/* BMW AG */
/* All rights reserved */
/* Description: LIN Description file */
/* Konfiguration: UKL_KW17_15 [13] */
/* Konfigurationsstand: F056-16-11-400 (Freeze KW17/15) */
/* Bus: M_LIN_6_V2 */

LIN_description_file;
LIN_protocol_version = "2.2";
LIN_language_version = "2.2";
LIN_speed = 19.2 kbps;
Channel_name = "M_LIN_6";

Nodes {
  Master: DME1_BK, 10 ms, 0.1 ms ;
  Slaves: EWP20, EWP22, EWP23 ;
}

Signals {
  AVL_VL_RPM_EWP20_LIN: 8, 255, EWP20, DME1_BK ;
  AVL_VL_RPM_EWP22_LIN: 8, 255, EWP22, DME1_BK ;
  AVL_VL_RPM_EWP23_LIN: 8, 255, EWP23, DME1_BK ;
  COMM_ERR_EWP20_LIN: 1, 0, EWP20, DME1_BK ;
  COMM_ERR_EWP22_LIN: 1, 0, EWP22, DME1_BK ;
  COMM_ERR_EWP23_LIN: 1, 0, EWP23, DME1_BK ;
   ERR_ST_BLK_EWP20_LIN: 2, 3, EWP20, DME1_BK ;
  ERR_ST_BLK_EWP22_LIN: 2, 3, EWP22, DME1_BK ;
  ERR_ST_BLK_EWP23_LIN: 2, 3, EWP23, DME1_BK ;
  ERR_ST_DRYR_EWP20_LIN: 2, 3, EWP20, DME1_BK ;
  ERR_ST_DRYR_EWP22_LIN: 2, 3, EWP22, DME1_BK ;
  ERR_ST_DRYR_EWP23_LIN: 2, 3, EWP23, DME1_BK ;
  ERR_ST_ERR_EL_EWP20_LIN: 2, 3, EWP20, DME1_BK ;
  ERR_ST_ERR_EL_EWP22_LIN: 2, 3, EWP22, DME1_BK ;
  ERR_ST_ERR_EL_EWP23_LIN: 2, 3, EWP23, DME1_BK ;
  ERR_ST_OCU_EWP20_LIN: 2, 3, EWP20, DME1_BK ;
  ERR_ST_OCU_EWP22_LIN: 2, 3, EWP22, DME1_BK ;
  ERR_ST_OCU_EWP23_LIN: 2, 3, EWP23, DME1_BK ;
  ERR_ST_OTMP_EWP20_LIN: 2, 3, EWP20, DME1_BK ;
  ERR_ST_OTMP_EWP22_LIN: 2, 3, EWP22, DME1_BK ;
  ERR_ST_OTMP_EWP23_LIN: 2, 3, EWP23, DME1_BK ;
  ERR_ST_U_EWP20_LIN: 2, 3, EWP20, DME1_BK ;
  ERR_ST_U_EWP22_LIN: 2, 3, EWP22, DME1_BK ;
  ERR_ST_U_EWP23_LIN: 2, 3, EWP23, DME1_BK ;
  I_EWP20_LIN: 8, 255, EWP20, DME1_BK ;
  I_EWP22_LIN: 8, 255, EWP22, DME1_BK ;
  I_EWP23_LIN: 8, 255, EWP23, DME1_BK ;
  ST_RPM_MONI_EWP20_LIN: 2, 3, EWP20, DME1_BK ;
  ST_RPM_MONI_EWP22_LIN: 2, 3, EWP22, DME1_BK ;
  ST_RPM_MONI_EWP23_LIN: 2, 3, EWP23, DME1_BK ;
  ST_TARVL_RPM_EWP20_LIN: 8, 255, EWP20, DME1_BK ;
  ST_TARVL_RPM_EWP22_LIN: 8, 255, EWP22, DME1_BK ;
  ST_TARVL_RPM_EWP23_LIN: 8, 255, EWP23, DME1_BK ;
  TARVL_RPM_EWP20_LIN: 8, 255, DME1_BK, EWP20 ;
  TARVL_RPM_EWP22_LIN: 8, 255, DME1_BK, EWP22 ;
  TARVL_RPM_EWP23_LIN: 8, 255, DME1_BK, EWP23 ;
  TEMP_EWP20_LIN: 8, 255, EWP20, DME1_BK ;
  TEMP_EWP22_LIN: 8, 255, EWP22, DME1_BK ;
  TEMP_EWP23_LIN: 8, 255, EWP23, DME1_BK ;
  U_EWP20_LIN: 8, 255, EWP20, DME1_BK ;
  U_EWP22_LIN: 8, 255, EWP22, DME1_BK ;
  U_EWP23_LIN: 8, 255, EWP23, DME1_BK ;
}

Frames {
  CTR_EWP20_LIN: 38, DME1_BK, 2 {
    TARVL_RPM_EWP20_LIN, 0 ;
  }
  CTR_EWP22_LIN: 40, DME1_BK, 2 {
    TARVL_RPM_EWP22_LIN, 0 ;
  }
  CTR_EWP23_LIN: 57, DME1_BK, 2 {
    TARVL_RPM_EWP23_LIN, 0 ;
  }
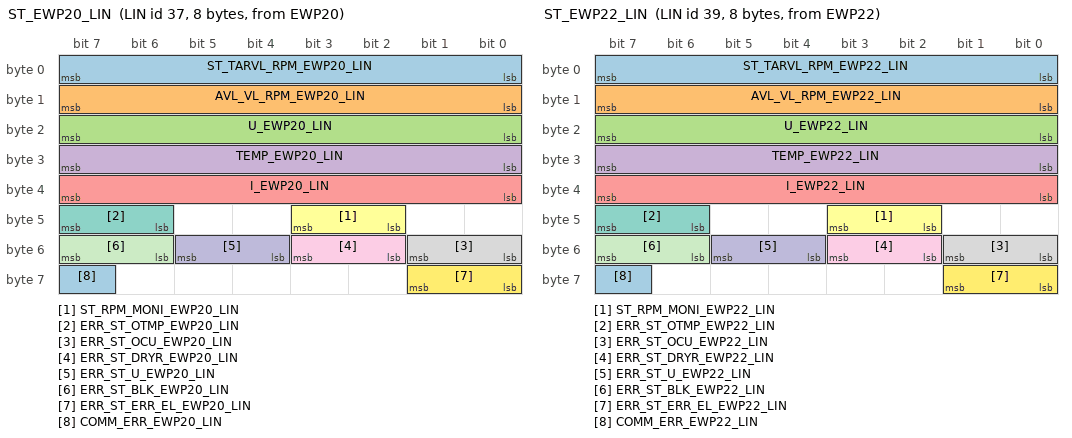
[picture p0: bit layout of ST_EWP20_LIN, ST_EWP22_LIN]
  ST_EWP20_LIN: 37, EWP20, 8 {
    ST_TARVL_RPM_EWP20_LIN, 0 ;
    AVL_VL_RPM_EWP20_LIN, 8 ;
    U_EWP20_LIN, 16 ;
    TEMP_EWP20_LIN, 24 ;
    I_EWP20_LIN, 32 ;
    ST_RPM_MONI_EWP20_LIN, 42 ;
    ERR_ST_OTMP_EWP20_LIN, 46 ;
    ERR_ST_OCU_EWP20_LIN, 48 ;
    ERR_ST_DRYR_EWP20_LIN, 50 ;
    ERR_ST_U_EWP20_LIN, 52 ;
    ERR_ST_BLK_EWP20_LIN, 54 ;
    ERR_ST_ERR_EL_EWP20_LIN, 56 ;
    COMM_ERR_EWP20_LIN, 63 ;
  }
  ST_EWP22_LIN: 39, EWP22, 8 {
    ST_TARVL_RPM_EWP22_LIN, 0 ;
    AVL_VL_RPM_EWP22_LIN, 8 ;
    U_EWP22_LIN, 16 ;
    TEMP_EWP22_LIN, 24 ;
    I_EWP22_LIN, 32 ;
    ST_RPM_MONI_EWP22_LIN, 42 ;
    ERR_ST_OTMP_EWP22_LIN, 46 ;
    ERR_ST_OCU_EWP22_LIN, 48 ;
    ERR_ST_DRYR_EWP22_LIN, 50 ;
    ERR_ST_U_EWP22_LIN, 52 ;
    ERR_ST_BLK_EWP22_LIN, 54 ;
    ERR_ST_ERR_EL_EWP22_LIN, 56 ;
    COMM_ERR_EWP22_LIN, 63 ;
  }
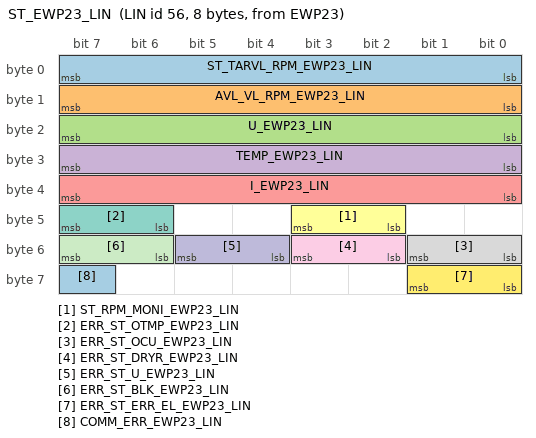
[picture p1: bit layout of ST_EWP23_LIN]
  ST_EWP23_LIN: 56, EWP23, 8 {
    ST_TARVL_RPM_EWP23_LIN, 0 ;
    AVL_VL_RPM_EWP23_LIN, 8 ;
    U_EWP23_LIN, 16 ;
    TEMP_EWP23_LIN, 24 ;
    I_EWP23_LIN, 32 ;
    ST_RPM_MONI_EWP23_LIN, 42 ;
    ERR_ST_OTMP_EWP23_LIN, 46 ;
    ERR_ST_OCU_EWP23_LIN, 48 ;
    ERR_ST_DRYR_EWP23_LIN, 50 ;
    ERR_ST_U_EWP23_LIN, 52 ;
    ERR_ST_BLK_EWP23_LIN, 54 ;
    ERR_ST_ERR_EL_EWP23_LIN, 56 ;
    COMM_ERR_EWP23_LIN, 63 ;
  }
}

Node_attributes {
  EWP20{
    LIN_protocol = "2.1" ;
    configured_NAD = 0x50 ;
    initial_NAD = 0x50 ;
    product_id = 0x40, 0x700F, 0 ;
    response_error = COMM_ERR_EWP20_LIN ;
    P2_min = 50 ms ;
    ST_min = 0 ms ;
    N_As_timeout = 1000 ms ;
    N_Cr_timeout = 1000 ms ;
    configurable_frames {
      ST_EWP20_LIN ;
      CTR_EWP20_LIN ;
    }
  }
  EWP22{
    LIN_protocol = "2.1" ;
    configured_NAD = 0x5A ;
    initial_NAD = 0x5A ;
    product_id = 0x40, 0x700F, 0 ;
    response_error = COMM_ERR_EWP22_LIN ;
    P2_min = 50 ms ;
    ST_min = 0 ms ;
    N_As_timeout = 1000 ms ;
    N_Cr_timeout = 1000 ms ;
    configurable_frames {
      ST_EWP22_LIN ;
      CTR_EWP22_LIN ;
    }
  }
  EWP23{
    LIN_protocol = "2.1" ;
    configured_NAD = 0x4B ;
    initial_NAD = 0x4B ;
    product_id = 0x40, 0x700F, 0 ;
    response_error = COMM_ERR_EWP23_LIN ;
    P2_min = 50 ms ;
    ST_min = 0 ms ;
    N_As_timeout = 1000 ms ;
    N_Cr_timeout = 1000 ms ;
    configurable_frames {
      ST_EWP23_LIN ;
      CTR_EWP23_LIN ;
    }
  }
}

Schedule_tables {
 DIAG {
    MasterReq delay 10 ms ;
    SlaveResp delay 10 ms ;
  }
 DIAG_RESP {
    SlaveResp delay 10 ms ;
  }
 DIAG_RQ {
    MasterReq delay 10 ms ;
  }
 RUN_EWP22 {
    CTR_EWP22_LIN delay 10 ms ;
    ST_EWP22_LIN delay 20 ms ;
  }
 RUN_EWP20 {
  CTR_EWP20_LIN delay 20 ms ;
    ST_EWP20_LIN delay 10 ms ;
  }
 RUN_EWP23 {
    CTR_EWP23_LIN delay 20 ms ;
  ST_EWP23_LIN delay 20 ms ;
  }
}

Signal_encoding_types {
  AVL_VL_RPM_EWP20_LIN {
    physical_value, 0, 254, 1, 0 ;
    logical_value, 255, "Signal ungultig" ;
  }
  COMM_ERR_EWP20_LIN {
    logical_value, 0, "kein Fehler" ;
    logical_value, 1, "Fehler aktiv" ;
  }
  ERR_ST_BLK_EWP20_LIN {
    logical_value, 0, "Keine Blockierung" ;
    logical_value, 1, "Blockierung" ;
    logical_value, 3, "BLK Signal ungultig" ;
  }
  ERR_ST_DRYR_EWP20_LIN {
    logical_value, 0, "kein Trockenlauf" ;
    logical_value, 1, "Trockenlauf" ;
    logical_value, 3, "DRYR Signal ungultig" ;
  }
  ERR_ST_ERR_EL_EWP20_LIN {
    logical_value, 0, "Kein interner Fehler erkannt" ;
    logical_value, 1, "Unplausible Temperatur-, Spannungs-, Strommessung erkannt" ;
    logical_value, 3, "ERR Signal ungultig" ;
  }
  ERR_ST_OCU_EWP20_LIN {
    logical_value, 0, "kein uberstrom" ;
    logical_value, 1, "Uberstromabschaltung" ;
    logical_value, 2, "Uberstromabregelung" ;
    logical_value, 3, "OCU Signal ungultig" ;
  }
  ERR_ST_OTMP_EWP20_LIN {
    logical_value, 0, "keine obertemperatur" ;
    logical_value, 1, "obertemperatur" ;
    logical_value, 2, "Abregeltemperatur" ;
    logical_value, 3, "OTMP Signal ungultig" ;
  }
  ERR_ST_U_EWP20_LIN {
    logical_value, 0, "Versorgungsspannung in Ordnung" ;
    logical_value, 1, "Unter-/uberspannung" ;
    logical_value, 3, "U Signal ungultig" ;
  }
  I_EWP20_LIN {
    physical_value, 0, 254, 0.2, 0, "A" ;
    logical_value, 255, "I Signal ungultig" ;
  }
  ST_RPM_MONI_EWP20_LIN {
    logical_value, 0, "Drehzahl?berwachung" ;
    logical_value, 1, "keine Drehzahl?berwachung" ;
    logical_value, 3, "RPM Signal ungultig" ;
  }
  ST_TARVL_RPM_EWP20_LIN {
    physical_value, 0, 254, 1, 0 ;
    logical_value, 255, "TARVL Signal ungultig" ;
  }
  TARVL_RPM_EWP20_LIN {
    physical_value, 0, 254, 1, 0 ;
    logical_value, 255, "TARRPN Signal ungultig" ;
  }
  TEMP_EWP20_LIN {
    physical_value, 0, 254, 1, -50, "C" ;
    logical_value, 255, "TMP Signal ungultig" ;
  }
  U_EWP20_LIN {
    physical_value, 0, 254, 0.1, 0, "V" ;
    logical_value, 255, "V Signal ungultig" ;
  }
}

Signal_representation {
  AVL_VL_RPM_EWP20_LIN: AVL_VL_RPM_EWP20_LIN, AVL_VL_RPM_EWP22_LIN, AVL_VL_RPM_EWP23_LIN ;
  COMM_ERR_EWP20_LIN: COMM_ERR_EWP20_LIN, COMM_ERR_EWP22_LIN, COMM_ERR_EWP23_LIN ;
  ERR_ST_BLK_EWP20_LIN: ERR_ST_BLK_EWP20_LIN, ERR_ST_BLK_EWP22_LIN, ERR_ST_BLK_EWP23_LIN ;
  ERR_ST_DRYR_EWP20_LIN: ERR_ST_DRYR_EWP20_LIN, ERR_ST_DRYR_EWP22_LIN, ERR_ST_DRYR_EWP23_LIN ;
  ERR_ST_ERR_EL_EWP20_LIN: ERR_ST_ERR_EL_EWP20_LIN, ERR_ST_ERR_EL_EWP22_LIN, ERR_ST_ERR_EL_EWP23_LIN ;
  ERR_ST_OCU_EWP20_LIN: ERR_ST_OCU_EWP20_LIN, ERR_ST_OCU_EWP22_LIN, ERR_ST_OCU_EWP23_LIN ;
  ERR_ST_OTMP_EWP20_LIN: ERR_ST_OTMP_EWP20_LIN, ERR_ST_OTMP_EWP22_LIN, ERR_ST_OTMP_EWP23_LIN ;
  ERR_ST_U_EWP20_LIN: ERR_ST_U_EWP20_LIN, ERR_ST_U_EWP22_LIN, ERR_ST_U_EWP23_LIN ;
  I_EWP20_LIN: I_EWP20_LIN, I_EWP22_LIN, I_EWP23_LIN ;
  ST_RPM_MONI_EWP20_LIN: ST_RPM_MONI_EWP20_LIN, ST_RPM_MONI_EWP22_LIN, ST_RPM_MONI_EWP23_LIN ;
  ST_TARVL_RPM_EWP20_LIN: ST_TARVL_RPM_EWP20_LIN, ST_TARVL_RPM_EWP22_LIN, ST_TARVL_RPM_EWP23_LIN ;
  TARVL_RPM_EWP20_LIN: TARVL_RPM_EWP20_LIN, TARVL_RPM_EWP22_LIN, TARVL_RPM_EWP23_LIN ;
  TEMP_EWP20_LIN: TEMP_EWP20_LIN, TEMP_EWP22_LIN, TEMP_EWP23_LIN ;
  U_EWP20_LIN: U_EWP20_LIN, U_EWP22_LIN, U_EWP23_LIN ;
}
